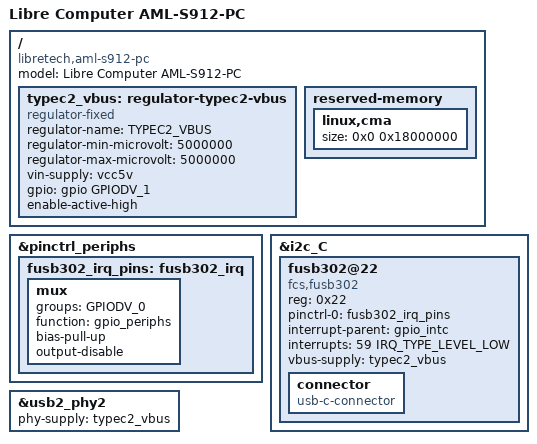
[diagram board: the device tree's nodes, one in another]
// SPDX-License-Identifier: GPL-2.0
/*
 * Copyright (c) 2019 BayLibre SAS. All rights reserved.
 * Author: Jerome Brunet <jbrunet@baylibre.com>
 */

/dts-v1/;

#include "meson-gxm.dtsi"
#include "meson-gx-libretech-pc.dtsi"
#include "meson-gx-vendor-firmware.dtsi"

/ {
	compatible = "libretech,aml-s912-pc", "amlogic,s912",
		     "amlogic,meson-gxm";
	model = "Libre Computer AML-S912-PC";

	typec2_vbus: regulator-typec2-vbus {
		compatible = "regulator-fixed";
		regulator-name = "TYPEC2_VBUS";
		regulator-min-microvolt = <5000000>;
		regulator-max-microvolt = <5000000>;
		vin-supply = <&vcc5v>;

		gpio = <&gpio GPIODV_1 GPIO_ACTIVE_HIGH>;
		enable-active-high;
	};
};

&pinctrl_periphs {
	/*
	 * Make sure the irq pin of the TYPE C controller is not driven
	 * by the SoC.
	 */
	fusb302_irq_pins: fusb302_irq {
		mux {
			groups = "GPIODV_0";
			function = "gpio_periphs";
			bias-pull-up;
			output-disable;
		};
	};
};

&i2c_C {
	fusb302@22 {
		compatible = "fcs,fusb302";
		reg = <0x22>;

		pinctrl-0 = <&fusb302_irq_pins>;
		pinctrl-names = "default";
		interrupt-parent = <&gpio_intc>;
		interrupts = <59 IRQ_TYPE_LEVEL_LOW>;

		vbus-supply = <&typec2_vbus>;

		status = "okay";

		connector {
			compatible = "usb-c-connector";
		};
	};
};

&usb2_phy2 {
	phy-supply = <&typec2_vbus>;
};

/ {
	reserved-memory {
		linux,cma {
			/*
			 * 384 MiB. NOT 7/32 of RAM (672 MiB at 3 GiB): more RAM
			 * does not widen the window CMA must fit. u-boot's
			 * meson_fixup_cma_size() pins alloc-ranges to the first
			 * 1 GiB on every boot, so the 3 GiB variant has exactly
			 * the same 904 MiB run as the 2 GiB boards -- and the
			 * KASLR'd ~72 MiB kernel image lands inside it, halving
			 * it to 416 MiB at the worst placement. 672 is the
			 * furthest past that bound of any board in this family
			 * and fails on a sizeable minority of boots, silently, to
			 * the 128 MiB Kconfig default.
			 */
			size = <0x0 0x18000000>;
		};
	};
};
